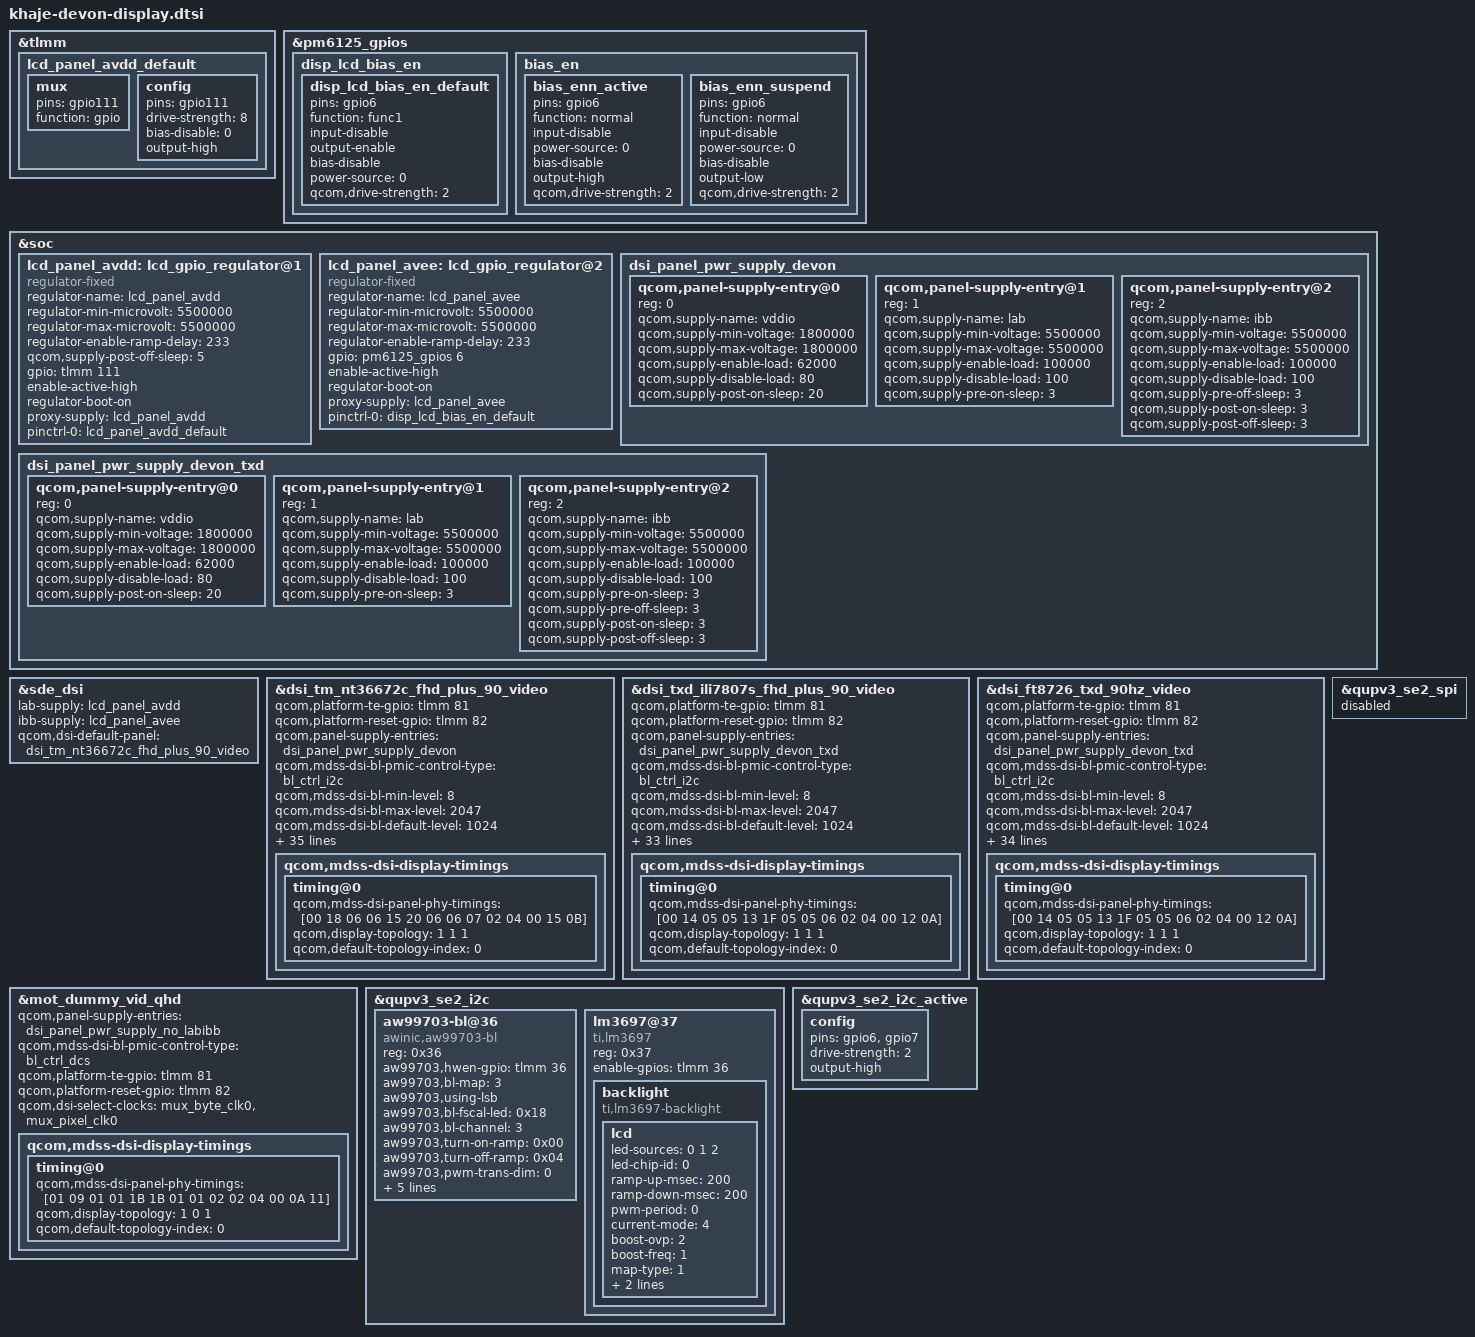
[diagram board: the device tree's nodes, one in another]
#include "dsi-panel-mot-tianma-nt36672c-649-1080x2400-vid.dtsi"
#include "dsi-panel-mot-txd-ili7807s-649-1080x2400-vid.dtsi"
#include "dsi-panel-mot-txd-ft8726-649-1080x2400-vid.dtsi"
#include "dsi-panel-mot-dummy-qhd-video.dtsi"

&tlmm {
	lcd_panel_avdd_default: lcd_panel_avdd_default {
		mux {
			pins = "gpio111";
			function = "gpio";
		};

		config {
			pins = "gpio111";
			drive-strength = <8>;
			bias-disable = <0>;
			output-high;
		};
	};
};

&pm6125_gpios {
        disp_lcd_bias_en {
                disp_lcd_bias_en_default: disp_lcd_bias_en_default {
                        pins = "gpio6";
                        function = "func1";
                        input-disable;
                        output-enable;
                        bias-disable;
                        power-source = <0>;
                        qcom,drive-strength = <2>;
                };
        };
	bias_en {
		bias_enn_active:bias_enn_active {
			pins = "gpio6";
			function = "normal";
			input-disable;
			power-source = <0>;
			bias-disable;
			output-high;
			qcom,drive-strength = <2>;
		};
		bias_enn_suspend:bias_enn_suspend {
			pins = "gpio6";
			function = "normal";
			input-disable;
			power-source = <0>;
			bias-disable;
			output-low;
			qcom,drive-strength = <2>;
		};
	};
};

&soc {
	lcd_panel_avdd: lcd_gpio_regulator@1 {
		compatible = "regulator-fixed";
		regulator-name = "lcd_panel_avdd";
		regulator-min-microvolt = <5500000>;
		regulator-max-microvolt = <5500000>;
		regulator-enable-ramp-delay = <233>;
		qcom,supply-post-off-sleep = <5>;
		gpio = <&tlmm 111 0>;
		enable-active-high;
		regulator-boot-on;
		proxy-supply = <&lcd_panel_avdd>;
		pinctrl-names = "default";
		pinctrl-0 = <&lcd_panel_avdd_default>;
	};

	lcd_panel_avee: lcd_gpio_regulator@2 {
		compatible = "regulator-fixed";
		regulator-name = "lcd_panel_avee";
		regulator-min-microvolt = <5500000>;
		regulator-max-microvolt = <5500000>;
		regulator-enable-ramp-delay = <233>;
		gpio = <&pm6125_gpios 6 0>;
		enable-active-high;
		regulator-boot-on;
		proxy-supply = <&lcd_panel_avee>;
		pinctrl-names = "default";
		pinctrl-0 = <&disp_lcd_bias_en_default>;
	};
};

&sde_dsi {
	lab-supply = <&lcd_panel_avdd>;
	ibb-supply = <&lcd_panel_avee>;

	qcom,dsi-default-panel = <&dsi_tm_nt36672c_fhd_plus_90_video>;
};

&soc {
	dsi_panel_pwr_supply_devon: dsi_panel_pwr_supply_devon{
		#address-cells = <1>;
		#size-cells = <0>;

		qcom,panel-supply-entry@0 {
			reg = <0>;
			qcom,supply-name = "vddio";
			qcom,supply-min-voltage = <1800000>;
			qcom,supply-max-voltage = <1800000>;
			qcom,supply-enable-load = <62000>;
			qcom,supply-disable-load = <80>;
			qcom,supply-post-on-sleep = <20>;
		};

		qcom,panel-supply-entry@1 {
			reg = <1>;
			qcom,supply-name = "lab";
			qcom,supply-min-voltage = <5500000>;
			qcom,supply-max-voltage = <5500000>;
			qcom,supply-enable-load = <100000>;
			qcom,supply-disable-load = <100>;
			qcom,supply-pre-on-sleep = <3>;
		};

		qcom,panel-supply-entry@2 {
			reg = <2>;
			qcom,supply-name = "ibb";
			qcom,supply-min-voltage = <5500000>;
			qcom,supply-max-voltage = <5500000>;
			qcom,supply-enable-load = <100000>;
			qcom,supply-disable-load = <100>;
			qcom,supply-pre-off-sleep = <3>;
			qcom,supply-post-on-sleep = <3>;
			qcom,supply-post-off-sleep = <3>;
		};

	};
};

&soc {
	dsi_panel_pwr_supply_devon_txd: dsi_panel_pwr_supply_devon_txd{
		#address-cells = <1>;
		#size-cells = <0>;

		qcom,panel-supply-entry@0 {
			reg = <0>;
			qcom,supply-name = "vddio";
			qcom,supply-min-voltage = <1800000>;
			qcom,supply-max-voltage = <1800000>;
			qcom,supply-enable-load = <62000>;
			qcom,supply-disable-load = <80>;
			qcom,supply-post-on-sleep = <20>;
		};

		qcom,panel-supply-entry@1 {
			reg = <1>;
			qcom,supply-name = "lab";
			qcom,supply-min-voltage = <5500000>;
			qcom,supply-max-voltage = <5500000>;
			qcom,supply-enable-load = <100000>;
			qcom,supply-disable-load = <100>;
			qcom,supply-pre-on-sleep = <3>;
		};

		qcom,panel-supply-entry@2 {
			reg = <2>;
			qcom,supply-name = "ibb";
			qcom,supply-min-voltage = <5500000>;
			qcom,supply-max-voltage = <5500000>;
			qcom,supply-enable-load = <100000>;
			qcom,supply-disable-load = <100>;
			qcom,supply-pre-on-sleep = <3>;
			qcom,supply-pre-off-sleep = <3>;
			qcom,supply-post-on-sleep = <3>;
			qcom,supply-post-off-sleep = <3>;
		};
	};
};

&dsi_tm_nt36672c_fhd_plus_90_video {
        qcom,platform-te-gpio = <&tlmm 81 0>;
        qcom,platform-reset-gpio = <&tlmm 82 0>;

	qcom,panel-supply-entries = <&dsi_panel_pwr_supply_devon>;
	qcom,mdss-dsi-bl-pmic-control-type = "bl_ctrl_i2c";
	qcom,mdss-dsi-bl-min-level = <8>;
	qcom,mdss-dsi-bl-max-level = <2047>;
	qcom,mdss-dsi-bl-default-level = <1024>;
	qcom,mdss-brightness-max-level = <2047>;
	qcom,bklt-dcs-2bytes-enabled;
	qcom,mdss-dsi-no-panel-on-read-support;
        qcom,mdss-dsi-reset-force-pull-low;
        qcom,disp_pre_reset;
        qcom,tp_state_check_enable;

	qcom,esd-check-enabled;
	qcom,mdss-dsi-panel-status-check-mode = "reg_read";
	qcom,mdss-dsi-panel-status-command = [06 01 00 01 00 00 01 ab
	06 01 00 01 00 00 01 0a];
	qcom,mdss-dsi-panel-status-command-state = "dsi_lp_mode";
	qcom,mdss-dsi-panel-status-value = <0x00 0x00>,<0x9c>;
	qcom,mdss-dsi-panel-on-check-value = <0x9c>;
	qcom,mdss-dsi-panel-status-read-length = <2 1>;
	qcom,mdss-dsi-panel-max-error-count = <3>;

        qcom,dsi-supported-dfps-list = <90 60>;
        qcom,mdss-dsi-pan-enable-dynamic-fps;
        qcom,mdss-dsi-pan-fps-update = "dfps_immediate_porch_mode_vfp";

	qcom,mdss-dsi-hbm-on-command = [39 01 00 00 00 00 03 51 07 FF];
	qcom,mdss-dsi-hbm-on-command-state =  "dsi_lp_mode";
	qcom,mdss-dsi-hbm-off-command = [39 01 00 00 00 00 03 51 06 66];
	qcom,mdss-dsi-hbm-off-command-state =  "dsi_lp_mode";
	qcom,mdss-dsi-hbm-type = "lcd-dcs-wled";

        qcom,dsi-select-clocks = "mux_byte_clk0", "mux_pixel_clk0";
	qcom,mdss-dsi-t-clk-post = <0x0B>;
	qcom,mdss-dsi-t-clk-pre = <0x15>;
	qcom,mdss-dsi-display-timings {
	timing@0 {
		qcom,mdss-dsi-panel-phy-timings = [00 18 06 06 15 20 06
	                                       06 07 02 04 00 15 0B];
	                qcom,display-topology = <1 1 1>;
	                qcom,default-topology-index = <0>;
	        };
	};
};



&dsi_txd_ili7807s_fhd_plus_90_video {
        qcom,platform-te-gpio = <&tlmm 81 0>;
        qcom,platform-reset-gpio = <&tlmm 82 0>;

        qcom,panel-supply-entries = <&dsi_panel_pwr_supply_devon_txd>;
        qcom,mdss-dsi-bl-pmic-control-type = "bl_ctrl_i2c";
        qcom,mdss-dsi-bl-min-level = <8>;
        qcom,mdss-dsi-bl-max-level = <2047>;
        qcom,mdss-dsi-bl-default-level = <1024>;
        qcom,mdss-brightness-max-level = <2047>;
	qcom,bklt-dcs-2bytes-enabled;
        qcom,mdss-dsi-no-panel-on-read-support;
        qcom,platform-reset-gpio-always-on;
        qcom,suspend-ulps-enabled;
        qcom,tp_state_check_enable;

        qcom,esd-check-enabled;
        qcom,mdss-dsi-panel-status-check-mode = "reg_read";
        qcom,mdss-dsi-panel-status-command = [06 01 00 01 00 00 01 0a];
        qcom,mdss-dsi-panel-status-command-state = "dsi_lp_mode";
        qcom,mdss-dsi-panel-status-value = <0x9c>;
        qcom,mdss-dsi-panel-on-check-value = <0x9c>;
        qcom,mdss-dsi-panel-status-read-length = <1>;

	qcom,mdss-dsi-hbm-on-command = [39 01 00 00 00 00 03 51 06 EF];
	qcom,mdss-dsi-hbm-on-command-state =  "dsi_lp_mode";
	qcom,mdss-dsi-hbm-off-command = [39 01 00 00 00 00 03 51 05 8B];
	qcom,mdss-dsi-hbm-off-command-state =  "dsi_lp_mode";
	qcom,mdss-dsi-hbm-type = "lcd-dcs-wled";

        qcom,dsi-supported-dfps-list = <90 60>;
        qcom,mdss-dsi-pan-enable-dynamic-fps;
        qcom,mdss-dsi-pan-fps-update = "dfps_immediate_porch_mode_vfp";

        qcom,dsi-select-clocks = "mux_byte_clk0", "mux_pixel_clk0";
        qcom,mdss-dsi-t-clk-post = <0x0A>;
        qcom,mdss-dsi-t-clk-pre = <0x12>;
        qcom,mdss-dsi-display-timings {
        timing@0 {
                qcom,mdss-dsi-panel-phy-timings = [00 14 05 05 13 1F 05
                                               05 06 02 04 00 12 0A];
                        qcom,display-topology = <1 1 1>;
                        qcom,default-topology-index = <0>;
                };
        };
};

&dsi_ft8726_txd_90hz_video {
        qcom,platform-te-gpio = <&tlmm 81 0>;
        qcom,platform-reset-gpio = <&tlmm 82 0>;

	qcom,panel-supply-entries = <&dsi_panel_pwr_supply_devon_txd>;
	qcom,mdss-dsi-bl-pmic-control-type = "bl_ctrl_i2c";
	qcom,mdss-dsi-bl-min-level = <8>;
	qcom,mdss-dsi-bl-max-level = <2047>;
	qcom,mdss-dsi-bl-default-level = <1024>;
	qcom,mdss-brightness-max-level = <2047>;
	qcom,bklt-dcs-2bytes-enabled;
	qcom,mdss-dsi-no-panel-on-read-support;
	qcom,platform-reset-gpio-always-on;
	qcom,mdss-panel-on-rst-pull-down;
        qcom,suspend-ulps-enabled;
        qcom,tp_state_check_enable;

	qcom,esd-check-enabled;
	qcom,mdss-dsi-panel-status-check-mode = "reg_read";
	qcom,mdss-dsi-panel-status-command = [06 01 00 01 00 00 01 0a];
	qcom,mdss-dsi-panel-status-command-state = "dsi_lp_mode";
	qcom,mdss-dsi-panel-status-value = <0x9c>;
	qcom,mdss-dsi-panel-on-check-value = <0x9c>;
	qcom,mdss-dsi-panel-status-read-length = <1>;

        qcom,dsi-supported-dfps-list = <90 60>;
        qcom,mdss-dsi-pan-enable-dynamic-fps;
        qcom,mdss-dsi-pan-fps-update = "dfps_immediate_porch_mode_vfp";

	qcom,mdss-dsi-hbm-on-command = [39 01 00 00 00 00 03 51 FF 0F];
	qcom,mdss-dsi-hbm-on-command-state =  "dsi_lp_mode";
	qcom,mdss-dsi-hbm-off-command = [39 01 00 00 00 00 03 51 CC 0C];
	qcom,mdss-dsi-hbm-off-command-state =  "dsi_lp_mode";
	qcom,mdss-dsi-hbm-type = "lcd-dcs-wled";

        qcom,dsi-select-clocks = "mux_byte_clk0", "mux_pixel_clk0";
	qcom,mdss-dsi-t-clk-post = <0x0A>;
	qcom,mdss-dsi-t-clk-pre = <0x12>;
	qcom,mdss-dsi-display-timings {
	timing@0 {
		qcom,mdss-dsi-panel-phy-timings = [00 14 05 05 13 1F 05
	                                       05 06 02 04 00 12 0A];
	                qcom,display-topology = <1 1 1>;
	                qcom,default-topology-index = <0>;
	        };
	};
};

&mot_dummy_vid_qhd {
	qcom,panel-supply-entries = <&dsi_panel_pwr_supply_no_labibb>;
	qcom,mdss-dsi-bl-pmic-control-type = "bl_ctrl_dcs";
        qcom,platform-te-gpio = <&tlmm 81 0>;
        qcom,platform-reset-gpio = <&tlmm 82 0>;

	qcom,dsi-select-clocks = "mux_byte_clk0", "mux_pixel_clk0";
	qcom,mdss-dsi-display-timings {
		timing@0 {
			qcom,mdss-dsi-panel-phy-timings = [01 09 01 01 1B 1B 01
					01 02 02 04 00 0A 11];
			qcom,display-topology = <1 0 1>;
			qcom,default-topology-index = <0>;
		};
	};
};

&qupv3_se2_i2c {
	status = "ok";

	aw99703-bl@36 {
		compatible = "awinic,aw99703-bl";
		reg = <0x36>;
		aw99703,hwen-gpio = <&tlmm 36 0>;
		aw99703,bl-map = <3>; /* brightness map level 1:256,2:1024,3:2048 */
		aw99703,using-lsb;
		aw99703,bl-fscal-led = <0x18>; /* 24mA */
		aw99703,bl-channel = <3>;
		aw99703,turn-on-ramp = <0x00>; /* 512us */
		aw99703,turn-off-ramp = <0x04>; /* 8ms */
		aw99703,pwm-trans-dim = <0>; /* 2ms */
		aw99703,i2c-trans-dim = <0x00>;
		aw99703,pwm-mode = <1>; /* 0 pwm disble,1 PWM enable */
		aw99703,map-type = <4>; /* 0 exponential, 4 linear */
		aw99703,work-mode = <1>; /* backlight */
		aw99703,default-brightness = <1810>;
	};

        lm3697@37 {
                compatible = "ti,lm3697";
                reg = <0x37>;

		/* TI, lm3697*/
		enable-gpios = <&tlmm 36 0>;
		backlight {
			compatible = "ti,lm3697-backlight";
			lcd {
				led-sources = <0 1 2>;
				led-chip-id = <0>;
				ramp-up-msec = <200>;
				ramp-down-msec = <200>;
				pwm-period = <0>;
				current-mode = <4>;	/*4: 23.4mA*/
				boost-ovp = <2>;	/*0:16v 1:24v 2:32v 3:40v*/
				boost-freq = <1>;	/*0:500Khz 1:1Mhz*/
				map-type = <1>; 	/* 0 exponential, 1 linear */
				current-align-type = <1>;/* 0 none, 1 aw99703, for exp mode current align*/
				default-brightness-level = <1023>;
			};
		};
	};

};

&qupv3_se2_i2c_active {
	/delete-node/ config;
	config {
		pins = "gpio6", "gpio7";
		drive-strength = <2>;
		output-high;
	};
};

&qupv3_se2_spi {
	#address-cells = <1>;
	#size-cells = <0>;

	status = "disabled";

};

